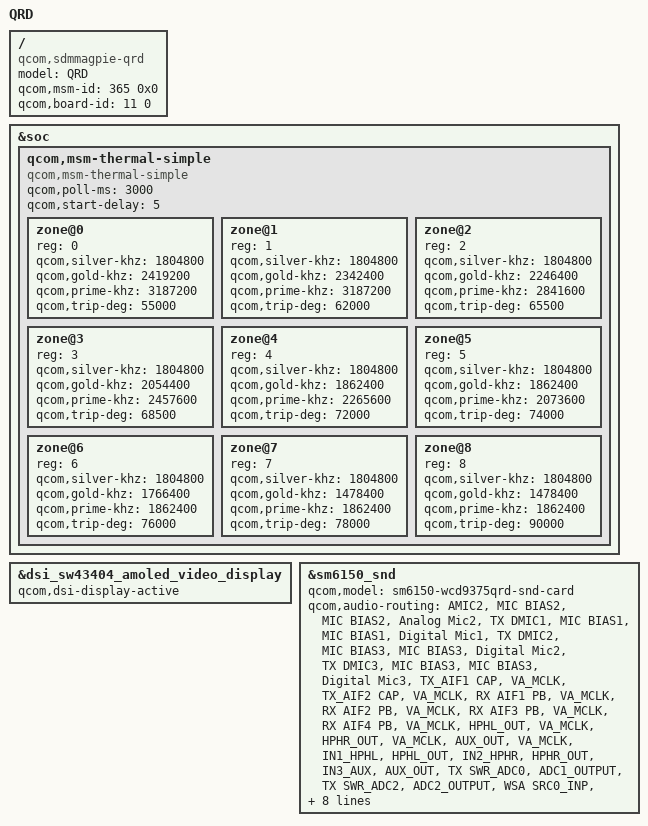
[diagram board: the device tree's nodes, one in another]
/* Copyright (c) 2018, The Linux Foundation. All rights reserved.
 *
 * This program is free software; you can redistribute it and/or modify
 * it under the terms of the GNU General Public License version 2 and
 * only version 2 as published by the Free Software Foundation.
 *
 * This program is distributed in the hope that it will be useful,
 * but WITHOUT ANY WARRANTY; without even the implied warranty of
 * MERCHANTABILITY or FITNESS FOR A PARTICULAR PURPOSE.  See the
 * GNU General Public License for more details.
 */

/dts-v1/;
/plugin/;

#include <dt-bindings/interrupt-controller/arm-gic.h>
#include <dt-bindings/clock/qcom,camcc-sdmmagpie.h>

#include "sdmmagpie-audio-overlay.dtsi"
#include "sdmmagpie-qrd.dtsi"

// Simple MSM Thermal Solution for Alioth
&soc {
	qcom,msm-thermal-simple {
		compatible = "qcom,msm-thermal-simple";
		qcom,poll-ms = <3000>;
		qcom,start-delay = <5>;

		zone@0 {
			reg = <0>;
			qcom,silver-khz = <1804800>;
			qcom,gold-khz = <2419200>;
			qcom,prime-khz = <3187200>;
			qcom,trip-deg = <55000>;
		};

		zone@1 {
			reg = <1>;
			qcom,silver-khz = <1804800>;
			qcom,gold-khz = <2342400>;
			qcom,prime-khz = <3187200>;
			qcom,trip-deg = <62000>;
		};

		zone@2 {
			reg = <2>;
			qcom,silver-khz = <1804800>;
			qcom,gold-khz = <2246400>;
			qcom,prime-khz = <2841600>;
			qcom,trip-deg = <65500>;
		};

		zone@3 {
			reg = <3>;
			qcom,silver-khz = <1804800>;
			qcom,gold-khz = <2054400>;
			qcom,prime-khz = <2457600>;
			qcom,trip-deg = <68500>;
		};

		zone@4 {
			reg = <4>;
			qcom,silver-khz = <1804800>;
			qcom,gold-khz = <1862400>;
			qcom,prime-khz = <2265600>;
			qcom,trip-deg = <72000>;
		};

		zone@5 {
			reg = <5>;
			qcom,silver-khz = <1804800>;
			qcom,gold-khz = <1862400>;
			qcom,prime-khz = <2073600>;
			qcom,trip-deg = <74000>;
		};

		zone@6 {
			reg = <6>;
			qcom,silver-khz = <1804800>;
			qcom,gold-khz = <1766400>;
			qcom,prime-khz = <1862400>;
			qcom,trip-deg = <76000>;
		};

		zone@7 {
			reg = <7>;
			qcom,silver-khz = <1804800>;
			qcom,gold-khz = <1478400>;
			qcom,prime-khz = <1862400>;
			qcom,trip-deg = <78000>;
		};


		zone@8 {
			reg = <8>;
			qcom,silver-khz = <1804800>;
			qcom,gold-khz = <1478400>;
			qcom,prime-khz = <1862400>;
			qcom,trip-deg = <90000>;
		};
	};
};

/ {
	model = "QRD";
	compatible = "qcom,sdmmagpie-qrd", "qcom,sdmmagpie", "qcom,qrd";
	qcom,msm-id = <365 0x0>;
	qcom,board-id = <11 0>;
};

&dsi_sw43404_amoled_video_display {
	qcom,dsi-display-active;
};

&sm6150_snd {
	qcom,model = "sm6150-wcd9375qrd-snd-card";
	qcom,audio-routing =
		"AMIC2", "MIC BIAS2",
		"MIC BIAS2", "Analog Mic2",
		"TX DMIC1", "MIC BIAS1",
		"MIC BIAS1", "Digital Mic1",
		"TX DMIC2", "MIC BIAS3",
		"MIC BIAS3", "Digital Mic2",
		"TX DMIC3", "MIC BIAS3",
		"MIC BIAS3", "Digital Mic3",
		"TX_AIF1 CAP", "VA_MCLK",
		"TX_AIF2 CAP", "VA_MCLK",
		"RX AIF1 PB", "VA_MCLK",
		"RX AIF2 PB", "VA_MCLK",
		"RX AIF3 PB", "VA_MCLK",
		"RX AIF4 PB", "VA_MCLK",
		"HPHL_OUT", "VA_MCLK",
		"HPHR_OUT", "VA_MCLK",
		"AUX_OUT", "VA_MCLK",
		"IN1_HPHL", "HPHL_OUT",
		"IN2_HPHR", "HPHR_OUT",
		"IN3_AUX", "AUX_OUT",
		"TX SWR_ADC0", "ADC1_OUTPUT",
		"TX SWR_ADC2", "ADC2_OUTPUT",
		"WSA SRC0_INP", "SRC0",
		"WSA_TX DEC0_INP", "TX DEC0 MUX",
		"WSA_TX DEC1_INP", "TX DEC1 MUX",
		"RX_TX DEC0_INP", "TX DEC0 MUX",
		"RX_TX DEC1_INP", "TX DEC1 MUX",
		"RX_TX DEC2_INP", "TX DEC2 MUX",
		"RX_TX DEC3_INP", "TX DEC3 MUX",
		"SpkrLeft IN", "WSA_SPK1 OUT",
		"WSA_SPK1 OUT", "VA_MCLK";
	qcom,wsa-max-devs = <0>;
	/*qcom,wsa-devs = <&wsa881x_0211>, <&wsa881x_0213>;*/
	qcom,wsa-aux-dev-prefix = "SpkrLeft", "SpkrLeft";
};
